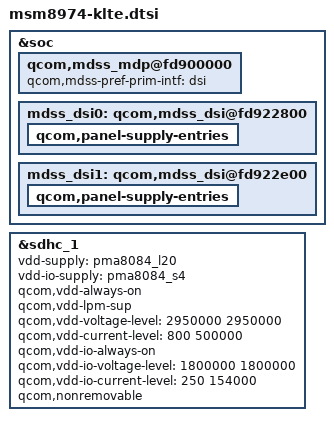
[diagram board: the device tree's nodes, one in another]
/* Copyright (c) 2012-2013, The Linux Foundation. All rights reserved.
 *
 * This program is free software; you can redistribute it and/or modify
 * it under the terms of the GNU General Public License version 2 and
 * only version 2 as published by the Free Software Foundation.
 *
 * This program is distributed in the hope that it will be useful,
 * but WITHOUT ANY WARRANTY; without even the implied warranty of
 * MERCHANTABILITY or FITNESS FOR A PARTICULAR PURPOSE.  See the
 * GNU General Public License for more details.
 */

#include "dsi_panel_samsung_octa_1080p_cmd_s6e3fa2.dtsi"

&soc {

	qcom,mdss_mdp@fd900000 {
		qcom,mdss-pref-prim-intf = "dsi";
	};

	mdss_dsi0: qcom,mdss_dsi@fd922800 {
		qcom,panel-supply-entries {
			/delete-property/ qcom,panel-supply-entry@0;
		};
	};

	mdss_dsi1: qcom,mdss_dsi@fd922e00 {
		qcom,panel-supply-entries {
			/delete-property/ qcom,panel-supply-entry@0;
		};
	};
};

&sdhc_1 {
	vdd-supply = <&pma8084_l20>;
	vdd-io-supply = <&pma8084_s4>;

	qcom,vdd-always-on;
	qcom,vdd-lpm-sup;
	qcom,vdd-voltage-level = <2950000 2950000>;
	qcom,vdd-current-level = <800 500000>;

	qcom,vdd-io-always-on;
	qcom,vdd-io-voltage-level = <1800000 1800000>;
	qcom,vdd-io-current-level = <250 154000>;

	qcom,nonremovable;
	status = "ok";
};
